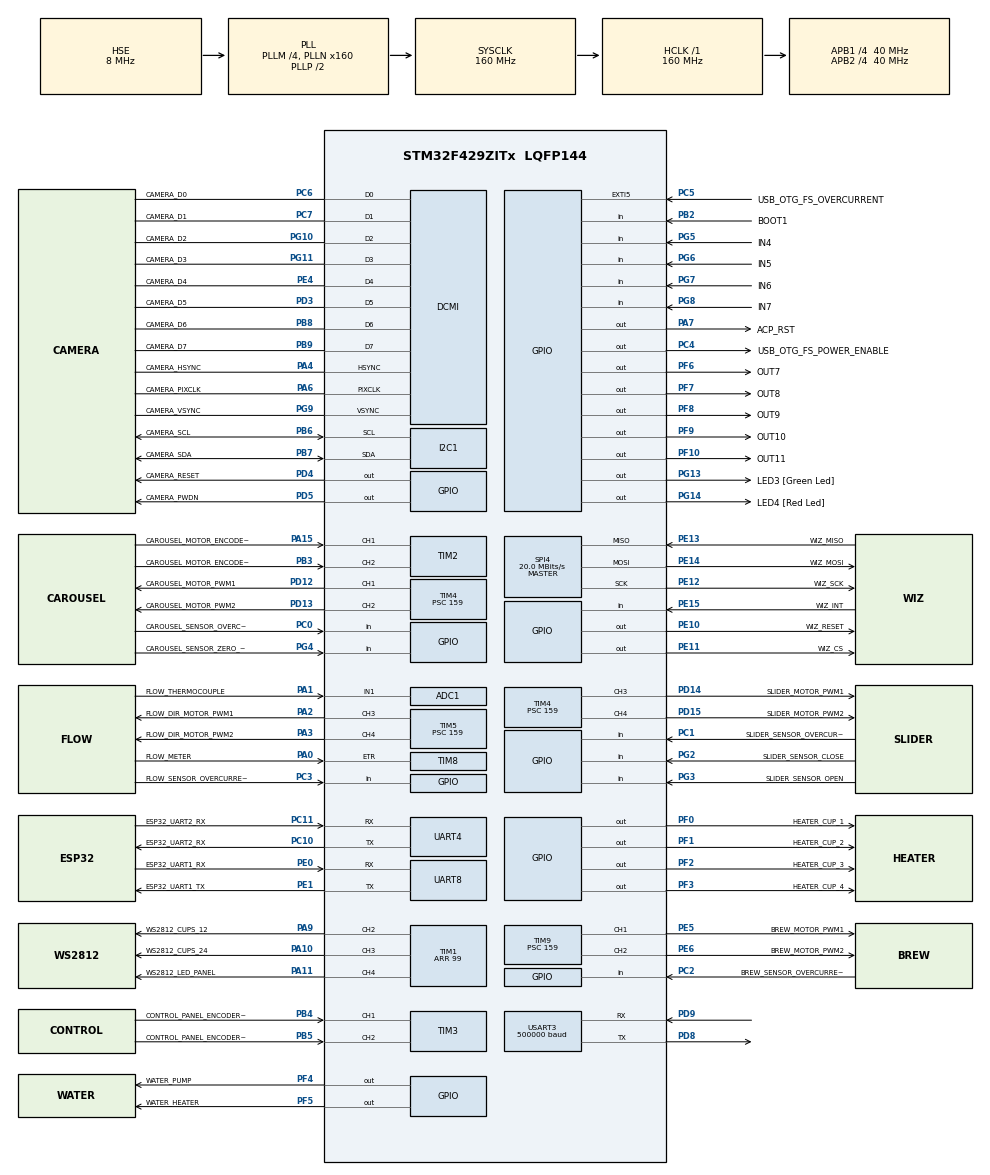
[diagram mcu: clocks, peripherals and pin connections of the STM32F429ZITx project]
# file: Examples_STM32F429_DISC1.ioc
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ADC1.Channel-0\#ChannelRegularConversion=ADC_CHANNEL_1
ADC1.NbrOfConversionFlag=1
ADC1.Rank-0\#ChannelRegularConversion=1
ADC1.SamplingTime-0\#ChannelRegularConversion=ADC_SAMPLETIME_3CYCLES
ADC1.master=1
DCMI.JPEGMode=DCMI_JPEG_ENABLE
DCMI.PCKPolarity=DCMI_PCKPOLARITY_RISING
Dma.DCMI.1.Direction=DMA_PERIPH_TO_MEMORY
Dma.DCMI.1.FIFOMode=DMA_FIFOMODE_DISABLE
Dma.DCMI.1.Instance=DMA2_Stream1
Dma.DCMI.1.MemDataAlignment=DMA_MDATAALIGN_WORD
Dma.DCMI.1.MemInc=DMA_MINC_ENABLE
Dma.DCMI.1.Mode=DMA_NORMAL
Dma.DCMI.1.PeriphDataAlignment=DMA_PDATAALIGN_WORD
Dma.DCMI.1.PeriphInc=DMA_PINC_DISABLE
Dma.DCMI.1.Priority=DMA_PRIORITY_LOW
Dma.Request0=USART3_RX
Dma.Request1=DCMI
Dma.Request2=TIM1_UP
Dma.Request3=UART8_RX
Dma.Request4=UART8_TX
Dma.Request5=UART4_RX
Dma.Request6=UART4_TX
Dma.TIM1_UP.2.Direction=DMA_MEMORY_TO_PERIPH
Dma.TIM1_UP.2.FIFOMode=DMA_FIFOMODE_DISABLE
Dma.TIM1_UP.2.Instance=DMA2_Stream5
Dma.TIM1_UP.2.MemDataAlignment=DMA_MDATAALIGN_HALFWORD
Dma.TIM1_UP.2.MemInc=DMA_MINC_ENABLE
Dma.TIM1_UP.2.Mode=DMA_NORMAL
Dma.TIM1_UP.2.PeriphDataAlignment=DMA_PDATAALIGN_HALFWORD
Dma.TIM1_UP.2.PeriphInc=DMA_PINC_DISABLE
Dma.TIM1_UP.2.Priority=DMA_PRIORITY_LOW
Dma.UART4_RX.5.Direction=DMA_PERIPH_TO_MEMORY
Dma.UART4_RX.5.FIFOMode=DMA_FIFOMODE_DISABLE
Dma.UART4_RX.5.Instance=DMA1_Stream2
Dma.UART4_RX.5.MemDataAlignment=DMA_MDATAALIGN_BYTE
Dma.UART4_RX.5.MemInc=DMA_MINC_ENABLE
Dma.UART4_RX.5.Mode=DMA_NORMAL
Dma.UART4_RX.5.PeriphDataAlignment=DMA_PDATAALIGN_BYTE
Dma.UART4_RX.5.PeriphInc=DMA_PINC_DISABLE
Dma.UART4_RX.5.Priority=DMA_PRIORITY_LOW
Dma.UART4_TX.6.Direction=DMA_MEMORY_TO_PERIPH
Dma.UART4_TX.6.FIFOMode=DMA_FIFOMODE_DISABLE
Dma.UART4_TX.6.Instance=DMA1_Stream4
Dma.UART4_TX.6.MemDataAlignment=DMA_MDATAALIGN_BYTE
Dma.UART4_TX.6.MemInc=DMA_MINC_ENABLE
Dma.UART4_TX.6.Mode=DMA_NORMAL
Dma.UART4_TX.6.PeriphDataAlignment=DMA_PDATAALIGN_BYTE
Dma.UART4_TX.6.PeriphInc=DMA_PINC_DISABLE
Dma.UART4_TX.6.Priority=DMA_PRIORITY_LOW
Dma.UART8_RX.3.Direction=DMA_PERIPH_TO_MEMORY
Dma.UART8_RX.3.FIFOMode=DMA_FIFOMODE_DISABLE
Dma.UART8_RX.3.Instance=DMA1_Stream6
Dma.UART8_RX.3.MemDataAlignment=DMA_MDATAALIGN_BYTE
Dma.UART8_RX.3.MemInc=DMA_MINC_ENABLE
Dma.UART8_RX.3.Mode=DMA_NORMAL
Dma.UART8_RX.3.PeriphDataAlignment=DMA_PDATAALIGN_BYTE
Dma.UART8_RX.3.PeriphInc=DMA_PINC_DISABLE
Dma.UART8_RX.3.Priority=DMA_PRIORITY_LOW
Dma.UART8_TX.4.Direction=DMA_MEMORY_TO_PERIPH
Dma.UART8_TX.4.FIFOMode=DMA_FIFOMODE_DISABLE
Dma.UART8_TX.4.Instance=DMA1_Stream0
Dma.UART8_TX.4.MemDataAlignment=DMA_MDATAALIGN_BYTE
Dma.UART8_TX.4.MemInc=DMA_MINC_ENABLE
Dma.UART8_TX.4.Mode=DMA_NORMAL
Dma.UART8_TX.4.PeriphDataAlignment=DMA_PDATAALIGN_BYTE
Dma.UART8_TX.4.PeriphInc=DMA_PINC_DISABLE
Dma.UART8_TX.4.Priority=DMA_PRIORITY_LOW
Dma.USART3_RX.0.Direction=DMA_PERIPH_TO_MEMORY
Dma.USART3_RX.0.FIFOMode=DMA_FIFOMODE_DISABLE
Dma.USART3_RX.0.Instance=DMA1_Stream1
Dma.USART3_RX.0.MemDataAlignment=DMA_MDATAALIGN_BYTE
Dma.USART3_RX.0.MemInc=DMA_MINC_ENABLE
Dma.USART3_RX.0.Mode=DMA_CIRCULAR
Dma.USART3_RX.0.PeriphDataAlignment=DMA_PDATAALIGN_BYTE
Dma.USART3_RX.0.PeriphInc=DMA_PINC_DISABLE
Dma.USART3_RX.0.Priority=DMA_PRIORITY_LOW
Mcu.Family=STM32F4
Mcu.Name=STM32F429ZITx
Mcu.Package=LQFP144
NVIC.DCMI_IRQn=true\:8\:0\:true\:false\:true\:true\:true\:true
NVIC.DMA1_Stream0_IRQn=true\:0\:0\:false\:false\:true\:false\:true\:true
NVIC.DMA1_Stream1_IRQn=true\:4\:0\:true\:false\:true\:false\:true\:true
NVIC.DMA1_Stream2_IRQn=true\:4\:0\:true\:false\:true\:false\:true\:true
NVIC.DMA1_Stream4_IRQn=true\:4\:0\:true\:false\:true\:false\:true\:true
NVIC.DMA1_Stream6_IRQn=true\:4\:0\:true\:false\:true\:false\:true\:true
NVIC.DMA2_Stream1_IRQn=true\:4\:0\:true\:false\:true\:false\:true\:true
NVIC.DMA2_Stream5_IRQn=true\:4\:0\:true\:false\:true\:false\:true\:true
NVIC.PriorityGroup=NVIC_PRIORITYGROUP_4
NVIC.TIM7_IRQn=true\:7\:0\:true\:false\:true\:true\:false\:true
NVIC.USART3_IRQn=true\:5\:0\:true\:false\:true\:true\:false\:true
PA0/WKUP.GPIO_Label=FLOW_METER
PA0/WKUP.Signal=S_TIM8_ETR
PA1.GPIO_Label=FLOW_THERMOCOUPLE
PA1.Signal=ADCx_IN1
PA10.GPIO_Label=WS2812_CUPS_24
PA10.Signal=S_TIM1_CH3
PA11.GPIO_Label=WS2812_LED_PANEL
PA11.Signal=S_TIM1_CH4
PA13.GPIO_Label=SWDIO
PA13.Mode=Serial_Wire
PA13.Signal=SYS_JTMS-SWDIO
PA14.GPIO_Label=SWCLK
PA14.Mode=Serial_Wire
PA14.Signal=SYS_JTCK-SWCLK
PA15.GPIO_Label=CAROUSEL_MOTOR_ENCODER_A
PA15.Signal=S_TIM2_CH1_ETR
PA2.GPIO_Label=FLOW_DIR_MOTOR_PWM1
PA2.Signal=S_TIM5_CH3
PA3.GPIO_Label=FLOW_DIR_MOTOR_PWM2
PA3.Signal=S_TIM5_CH4
PA4.GPIO_Label=CAMERA_HSYNC
PA4.Mode=Slave_8_bits_External_Synchro
PA4.Signal=DCMI_HSYNC
PA6.GPIO_Label=CAMERA_PIXCLK
PA6.Mode=Slave_8_bits_External_Synchro
PA6.Signal=DCMI_PIXCLK
PA7.GPIO_Label=ACP_RST
PA7.GPIO_Mode=GPIO_MODE_OUTPUT_PP
PA7.GPIO_PuPd=GPIO_NOPULL
PA7.GPIO_Speed=GPIO_SPEED_FREQ_LOW
PA7.Signal=GPIO_Output
PA9.GPIO_Label=WS2812_CUPS_12
PA9.Signal=S_TIM1_CH2
PB12.GPIO_Label=OTG_HS_ID
PB12.GPIO_Mode=GPIO_MODE_AF_PP
PB12.GPIO_PuPd=GPIO_NOPULL
PB12.GPIO_Speed=GPIO_SPEED_FREQ_LOW
PB12.Signal=USB_OTG_HS_ID
PB13.GPIO_Label=VBUS_HS
PB13.GPIO_Mode=GPIO_MODE_INPUT
PB13.GPIO_PuPd=GPIO_NOPULL
PB13.Signal=USB_OTG_HS_VBUS
PB14.GPIO_Label=OTG_HS_DM
PB14.GPIO_Mode=GPIO_MODE_AF_PP
PB14.GPIO_PuPd=GPIO_NOPULL
PB14.GPIO_Speed=GPIO_SPEED_FREQ_LOW
PB14.Signal=USB_OTG_HS_DM
PB15.GPIO_Label=OTG_HS_DP
PB15.GPIO_Mode=GPIO_MODE_AF_PP
PB15.GPIO_PuPd=GPIO_NOPULL
PB15.GPIO_Speed=GPIO_SPEED_FREQ_LOW
PB15.Signal=USB_OTG_HS_DP
PB2/BOOT1.GPIO_Label=BOOT1
PB2/BOOT1.GPIO_Mode=GPIO_MODE_INPUT
PB2/BOOT1.GPIO_PuPd=GPIO_NOPULL
PB2/BOOT1.Signal=GPIO_Input
PB3.GPIO_Label=CAROUSEL_MOTOR_ENCODER_B
PB3.Signal=S_TIM2_CH2
PB4.GPIO_Label=CONTROL_PANEL_ENCODER_A
PB4.Signal=S_TIM3_CH1
PB5.GPIO_Label=CONTROL_PANEL_ENCODER_B
PB5.Signal=S_TIM3_CH2
PB6.GPIO_Label=CAMERA_SCL
PB6.GPIO_Pu=GPIO_PULLUP
PB6.Mode=I2C
PB6.Signal=I2C1_SCL
PB7.GPIO_Label=CAMERA_SDA
PB7.GPIO_Pu=GPIO_PULLUP
PB7.Mode=I2C
PB7.Signal=I2C1_SDA
PB8.GPIO_Label=CAMERA_D6
PB8.Mode=Slave_8_bits_External_Synchro
PB8.Signal=DCMI_D6
PB9.GPIO_Label=CAMERA_D7
PB9.Mode=Slave_8_bits_External_Synchro
PB9.Signal=DCMI_D7
PC0.GPIO_Label=CAROUSEL_SENSOR_OVERCURRENT
PC0.Signal=GPIO_Input
PC1.GPIO_Label=SLIDER_SENSOR_OVERCURRENT
PC1.Signal=GPIO_Input
PC10.GPIO_Label=ESP32_UART2_RX
PC10.Mode=Asynchronous
PC10.Signal=UART4_TX
PC11.GPIO_Label=ESP32_UART2_RX
PC11.Mode=Asynchronous
PC11.Signal=UART4_RX
PC14/OSC32_IN.Mode=LSE-External-Oscillator
PC14/OSC32_IN.Signal=RCC_OSC32_IN
PC15/OSC32_OUT.Mode=LSE-External-Oscillator
PC15/OSC32_OUT.Signal=RCC_OSC32_OUT
PC2.GPIO_Label=BREW_SENSOR_OVERCURRENT
PC2.Signal=GPIO_Input
PC3.GPIO_Label=FLOW_SENSOR_OVERCURRENT
PC3.Signal=GPIO_Input
PC4.GPIO_Label=USB_OTG_FS_POWER_ENABLE
PC4.GPIO_Mode=GPIO_MODE_OUTPUT_PP
PC4.GPIO_PuPd=GPIO_NOPULL
PC4.GPIO_Speed=GPIO_SPEED_FREQ_LOW
PC4.Signal=GPIO_Output
PC5.GPIO_Label=USB_OTG_FS_OVERCURRENT
PC5.GPIO_ModeDefaultEXTI=GPIO_MODE_EVT_RISING
PC5.Signal=GPXTI5
PC6.GPIO_Label=CAMERA_D0
PC6.Mode=Slave_8_bits_External_Synchro
PC6.Signal=DCMI_D0
PC7.GPIO_Label=CAMERA_D1
PC7.Mode=Slave_8_bits_External_Synchro
PC7.Signal=DCMI_D1
PD12.GPIO_Label=CAROUSEL_MOTOR_PWM1
PD12.Signal=S_TIM4_CH1
PD13.GPIO_Label=CAROUSEL_MOTOR_PWM2
PD13.Signal=S_TIM4_CH2
PD14.GPIO_Label=SLIDER_MOTOR_PWM1
PD14.Signal=S_TIM4_CH3
PD15.GPIO_Label=SLIDER_MOTOR_PWM2
PD15.Signal=S_TIM4_CH4
PD3.GPIO_Label=CAMERA_D5
PD3.Mode=Slave_8_bits_External_Synchro
PD3.Signal=DCMI_D5
PD4.GPIO_Label=CAMERA_RESET
PD4.Signal=GPIO_Output
PD5.GPIO_Label=CAMERA_PWDN
PD5.Signal=GPIO_Output
PD8.Mode=Asynchronous
PD8.Signal=USART3_TX
PD9.Mode=Asynchronous
PD9.Signal=USART3_RX
PE0.GPIO_Label=ESP32_UART1_RX
PE0.Mode=Asynchronous
PE0.Signal=UART8_RX
PE1.GPIO_Label=ESP32_UART1_TX
PE1.Mode=Asynchronous
PE1.Signal=UART8_TX
PE10.GPIO_Label=WIZ_RESET
PE10.Signal=GPIO_Output
PE11.GPIO_Label=WIZ_CS
PE11.Signal=GPIO_Output
PE12.GPIO_Label=WIZ_SCK
PE12.Mode=Full_Duplex_Master
PE12.Signal=SPI4_SCK
PE13.GPIO_Label=WIZ_MISO
PE13.Mode=Full_Duplex_Master
PE13.Signal=SPI4_MISO
PE14.GPIO_Label=WIZ_MOSI
PE14.Mode=Full_Duplex_Master
PE14.Signal=SPI4_MOSI
PE15.GPIO_Label=WIZ_INT
PE15.Signal=GPIO_Input
PE4.GPIO_Label=CAMERA_D4
PE4.Mode=Slave_8_bits_External_Synchro
PE4.Signal=DCMI_D4
PE5.GPIO_Label=BREW_MOTOR_PWM1
PE5.Signal=S_TIM9_CH1
PE6.GPIO_Label=BREW_MOTOR_PWM2
PE6.Signal=S_TIM9_CH2
PF0.GPIO_Label=HEATER_CUP_1
PF0.Signal=GPIO_Output
PF1.GPIO_Label=HEATER_CUP_2
PF1.Signal=GPIO_Output
PF10.GPIO_Label=OUT11
PF10.Signal=GPIO_Output
PF2.GPIO_Label=HEATER_CUP_3
PF2.Signal=GPIO_Output
PF3.GPIO_Label=HEATER_CUP_4
PF3.Signal=GPIO_Output
PF4.GPIO_Label=WATER_PUMP
PF4.Signal=GPIO_Output
PF5.GPIO_Label=WATER_HEATER
PF5.Signal=GPIO_Output
PF6.GPIO_Label=OUT7
PF6.Signal=GPIO_Output
PF7.GPIO_Label=OUT8
PF7.Signal=GPIO_Output
PF8.GPIO_Label=OUT9
PF8.Signal=GPIO_Output
PF9.GPIO_Label=OUT10
PF9.Signal=GPIO_Output
PG10.GPIO_Label=CAMERA_D2
PG10.Mode=Slave_8_bits_External_Synchro
PG10.Signal=DCMI_D2
PG11.GPIO_Label=CAMERA_D3
PG11.Mode=Slave_8_bits_External_Synchro
PG11.Signal=DCMI_D3
PG13.GPIO_Label=LED3 [Green Led]
PG13.GPIO_Mode=GPIO_MODE_OUTPUT_PP
PG13.GPIO_PuPd=GPIO_NOPULL
PG13.GPIO_Speed=GPIO_SPEED_FREQ_LOW
PG13.Signal=GPIO_Output
PG14.GPIO_Label=LED4 [Red Led]
PG14.GPIO_Mode=GPIO_MODE_OUTPUT_PP
PG14.GPIO_PuPd=GPIO_NOPULL
PG14.GPIO_Speed=GPIO_SPEED_FREQ_LOW
PG14.Signal=GPIO_Output
PG2.GPIO_Label=SLIDER_SENSOR_CLOSE
PG2.Signal=GPIO_Input
PG3.GPIO_Label=SLIDER_SENSOR_OPEN
PG3.Signal=GPIO_Input
PG4.GPIO_Label=CAROUSEL_SENSOR_ZERO_MARK
PG4.Signal=GPIO_Input
PG5.GPIO_Label=IN4
PG5.Signal=GPIO_Input
PG6.GPIO_Label=IN5
PG6.Signal=GPIO_Input
PG7.GPIO_Label=IN6
PG7.Signal=GPIO_Input
PG8.GPIO_Label=IN7
PG8.Signal=GPIO_Input
PG9.GPIO_Label=CAMERA_VSYNC
PG9.Mode=Slave_8_bits_External_Synchro
PG9.Signal=DCMI_VSYNC
PH0/OSC_IN.GPIO_Label=PH0-OSC_IN
PH0/OSC_IN.Mode=HSE-External-Oscillator
PH0/OSC_IN.Signal=RCC_OSC_IN
PH1/OSC_OUT.GPIO_Label=PH1-OSC_OUT
PH1/OSC_OUT.Mode=HSE-External-Oscillator
PH1/OSC_OUT.Signal=RCC_OSC_OUT
ProjectManager.HeapSize=0x500
ProjectManager.StackSize=0x500
ProjectManager.TargetToolchain=MDK-ARM V5.32
RCC.48MHZClocksFreq_Value=106666666.66666667
RCC.AHBFreq_Value=160000000
RCC.APB1CLKDivider=RCC_HCLK_DIV4
RCC.APB1Freq_Value=40000000
RCC.APB1TimFreq_Value=80000000
RCC.APB2CLKDivider=RCC_HCLK_DIV4
RCC.APB2Freq_Value=40000000
RCC.APB2TimFreq_Value=80000000
RCC.CortexFreq_Value=160000000
RCC.HCLKFreq_Value=160000000
RCC.HSE_VALUE=8000000
RCC.HSI_VALUE=16000000
RCC.PLLM=4
RCC.PLLN=160
RCC.PLLQ=3
RCC.PLLSAIN=50
RCC.PLLSourceVirtual=RCC_PLLSOURCE_HSE
RCC.SYSCLKFreq_VALUE=160000000
RCC.SYSCLKSource=RCC_SYSCLKSOURCE_PLLCLK
RCC.VCOOutputFreq_Value=320000000
SH.ADCx_IN1.0=ADC1_IN1,IN1
SH.S_TIM1_CH2.0=TIM1_CH2,PWM Generation2 CH2
SH.S_TIM1_CH3.0=TIM1_CH3,PWM Generation3 CH3
SH.S_TIM1_CH4.0=TIM1_CH4,PWM Generation4 CH4
SH.S_TIM2_CH1_ETR.0=TIM2_CH1,Encoder_Interface
SH.S_TIM2_CH2.0=TIM2_CH2,Encoder_Interface
SH.S_TIM3_CH1.0=TIM3_CH1,Encoder_Interface
SH.S_TIM3_CH2.0=TIM3_CH2,Encoder_Interface
SH.S_TIM4_CH1.0=TIM4_CH1,PWM Generation1 CH1
SH.S_TIM4_CH2.0=TIM4_CH2,PWM Generation2 CH2
SH.S_TIM4_CH3.0=TIM4_CH3,PWM Generation3 CH3
SH.S_TIM4_CH4.0=TIM4_CH4,PWM Generation4 CH4
SH.S_TIM5_CH3.0=TIM5_CH3,PWM Generation3 CH3
SH.S_TIM5_CH4.0=TIM5_CH4,PWM Generation4 CH4
SH.S_TIM8_ETR.0=TIM8_ETR,ClockSourceETR_Mode2
SH.S_TIM9_CH1.0=TIM9_CH1,PWM Generation1 CH1
SH.S_TIM9_CH2.0=TIM9_CH2,PWM Generation2 CH2
SPI4.CalculateBaudRate=20.0 MBits/s
SPI4.Direction=SPI_DIRECTION_2LINES
SPI4.Mode=SPI_MODE_MASTER
SPI4.VirtualType=VM_MASTER
TIM1.Channel-PWM\ Generation2\ CH2=TIM_CHANNEL_2
TIM1.Channel-PWM\ Generation3\ CH3=TIM_CHANNEL_3
TIM1.Channel-PWM\ Generation4\ CH4=TIM_CHANNEL_4
TIM1.Period=99
TIM1.TIM_MasterOutputTrigger=TIM_TRGO_UPDATE
TIM4.Channel-PWM\ Generation1\ CH1=TIM_CHANNEL_1
TIM4.Channel-PWM\ Generation2\ CH2=TIM_CHANNEL_2
TIM4.Channel-PWM\ Generation3\ CH3=TIM_CHANNEL_3
TIM4.Channel-PWM\ Generation4\ CH4=TIM_CHANNEL_4
TIM4.Period=9999
TIM4.Prescaler=159
TIM4.TIM_MasterOutputTrigger=TIM_TRGO_RESET
TIM5.Channel-PWM\ Generation3\ CH3=TIM_CHANNEL_3
TIM5.Channel-PWM\ Generation4\ CH4=TIM_CHANNEL_4
TIM5.Period=9999
TIM5.Prescaler=159
TIM7.Period=9999
TIM7.Prescaler=7999
TIM7.TIM_MasterOutputTrigger=TIM_TRGO_UPDATE
TIM9.Channel-PWM\ Generation1\ CH1=TIM_CHANNEL_1
TIM9.Channel-PWM\ Generation2\ CH2=TIM_CHANNEL_2
TIM9.Period=9999
TIM9.Prescaler=159
UART4.VirtualMode=Asynchronous
UART8.VirtualMode=Asynchronous
USART3.BaudRate=500000
USART3.VirtualMode=VM_ASYNC
VP_CRC_VS_CRC.Mode=CRC_Activate
VP_TIM1_VS_ClockSourceINT.Mode=Internal
VP_TIM4_VS_ClockSourceINT.Mode=Internal
VP_TIM5_VS_ClockSourceINT.Mode=Internal
VP_TIM7_VS_ClockSourceINT.Mode=Enable_Timer
board=STM32F429I-DISC1

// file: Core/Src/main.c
/* USER CODE BEGIN Header */
/**
  ******************************************************************************
  * @file           : main.c
  * @brief          : Main program body
  ******************************************************************************
  * @attention
  *
  * Copyright (c) 2022 STMicroelectronics.
  * All rights reserved.
  *
  * This software is licensed under terms that can be found in the LICENSE file
  * in the root directory of this software component.
  * If no LICENSE file comes with this software, it is provided AS-IS.
  *
  ******************************************************************************
  */
/* USER CODE END Header */
#include "main.h"
#include "adc.h"
#include "crc.h"
#include "dcmi.h"
#include "dma.h"
#include "i2c.h"
#include "spi.h"
#include "tim.h"
#include "usart.h"
#include "gpio.h"

/* USER CODE BEGIN Includes */
#include "Components.h"
/* USER CODE END Includes */

/* USER CODE BEGIN PV */
//------------------------------------------------------------------------------

//------------------------------------------------------------------------------
/* USER CODE END PV */

void SystemClock_Config(void);

int main(void)
{

  /* MCU Configuration--------------------------------------------------------*/

  /* Reset of all peripherals, Initializes the Flash interface and the Systick. */
  HAL_Init();

  /* Configure the system clock */
  SystemClock_Config();

  /* Initialize all configured peripherals */
  MX_GPIO_Init();
  MX_DMA_Init();
  MX_CRC_Init();
  MX_TIM1_Init();
  MX_TIM2_Init();
  MX_TIM3_Init();
  MX_TIM4_Init();
  MX_TIM5_Init();
  MX_TIM9_Init();
  MX_UART8_Init();
  MX_USART3_UART_Init();
  MX_UART4_Init();
  MX_DCMI_Init();
  MX_I2C1_Init();
  MX_SPI4_Init();
  MX_TIM8_Init();
  MX_ADC1_Init();
  MX_TIM7_Init();
  /* USER CODE BEGIN 2 */
	TerminalInit(main);

	LED3_GPIO_Port->ODR |= LED3_Pin;
	LED4_GPIO_Port->ODR &= ~LED4_Pin;
  /* USER CODE END 2 */

  /* Infinite loop */
  /* USER CODE BEGIN WHILE */
  while (1)
  {
		TerminalHandler();
    /* USER CODE END WHILE */

  }
}

void SystemClock_Config(void)
{
  RCC_OscInitTypeDef RCC_OscInitStruct = {0};
  RCC_ClkInitTypeDef RCC_ClkInitStruct = {0};

  /** Configure the main internal regulator output voltage
  */
  __HAL_RCC_PWR_CLK_ENABLE();
  __HAL_PWR_VOLTAGESCALING_CONFIG(PWR_REGULATOR_VOLTAGE_SCALE1);

  /** Initializes the RCC Oscillators according to the specified parameters
  * in the RCC_OscInitTypeDef structure.
  */
  RCC_OscInitStruct.OscillatorType = RCC_OSCILLATORTYPE_HSE;
  RCC_OscInitStruct.HSEState = RCC_HSE_ON;
  RCC_OscInitStruct.PLL.PLLState = RCC_PLL_ON;
  RCC_OscInitStruct.PLL.PLLSource = RCC_PLLSOURCE_HSE;
  RCC_OscInitStruct.PLL.PLLM = 4;
  RCC_OscInitStruct.PLL.PLLN = 160;
  RCC_OscInitStruct.PLL.PLLP = RCC_PLLP_DIV2;
  RCC_OscInitStruct.PLL.PLLQ = 3;
  if (HAL_RCC_OscConfig(&RCC_OscInitStruct) != HAL_OK)
  {
    Error_Handler();
  }

  /** Initializes the CPU, AHB and APB buses clocks
  */
  RCC_ClkInitStruct.ClockType = RCC_CLOCKTYPE_HCLK|RCC_CLOCKTYPE_SYSCLK
                              |RCC_CLOCKTYPE_PCLK1|RCC_CLOCKTYPE_PCLK2;
  RCC_ClkInitStruct.SYSCLKSource = RCC_SYSCLKSOURCE_PLLCLK;
  RCC_ClkInitStruct.AHBCLKDivider = RCC_SYSCLK_DIV1;
  RCC_ClkInitStruct.APB1CLKDivider = RCC_HCLK_DIV4;
  RCC_ClkInitStruct.APB2CLKDivider = RCC_HCLK_DIV4;

  if (HAL_RCC_ClockConfig(&RCC_ClkInitStruct, FLASH_LATENCY_5) != HAL_OK)
  {
    Error_Handler();
  }
}

void Error_Handler(void)
{
  __disable_irq();
  while (1)
  {
  }
}
